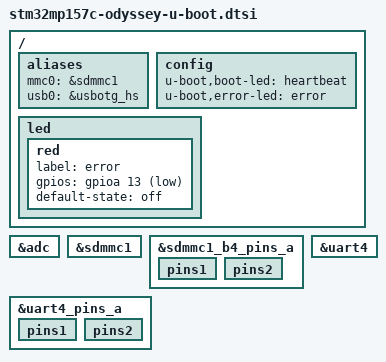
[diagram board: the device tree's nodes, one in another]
// SPDX-License-Identifier: GPL-2.0+ OR BSD-3-Clause
/*
 * Copyright (C) 2020 Marcin Sloniewski <marcin.sloniewski@gmail.com>
 */

 #include "stm32mp157c-odyssey-som-u-boot.dtsi"

/ {
	aliases {
		mmc0 = &sdmmc1;
		usb0 = &usbotg_hs;
	};
	config {
		u-boot,boot-led = "heartbeat";
		u-boot,error-led = "error";
	};
	led {
		red {
			label = "error";
			gpios = <&gpioa 13 GPIO_ACTIVE_LOW>;
			default-state = "off";
			status = "okay";
		};
	};
};

&adc {
	status = "okay";
};

&sdmmc1 {
	bootph-pre-ram;
};

&sdmmc1_b4_pins_a {
	bootph-pre-ram;
	pins1 {
		bootph-pre-ram;
	};
	pins2 {
		bootph-pre-ram;
	};
};

&uart4 {
	bootph-all;
};

&uart4_pins_a {
	bootph-all;
	pins1 {
		bootph-all;
	};
	pins2 {
		bootph-all;
	};
};

